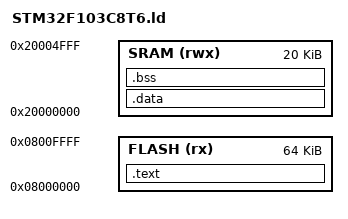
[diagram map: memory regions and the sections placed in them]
MEMORY
{
    FLASH (rx) : ORIGIN = 0x08000000, LENGTH = 64K
    SRAM (rwx) : ORIGIN = 0x20000000, LENGTH = 20K
}

ENTRY(Reset_Handler)

SECTIONS
{
    .text :
    {
        KEEP(*(.isr_vector))
        *(.text)
        *(.text*)
        *(.rodata)
        *(.rodata*)
        *(.glue_7)
        *(.glue_7t)
        *(.ARM.extab)
        *(.ARM.exidx)
        KEEP(*(.init))
        KEEP(*(.fini))
        KEEP(*(.preinit_array))
        KEEP(*(SORT_BY_INIT_PRIORITY(.init_array.*)))
        KEEP(*(.init_array))
        KEEP(*(SORT_BY_INIT_PRIORITY(.fini_array.*)))
        KEEP(*(.fini_array))
        . = ALIGN(4);
        _etext = .;
    } > FLASH

    _sidata = LOADADDR(.data);

    .data : AT (_etext)
    {
        _sdata = .;
        *(.data)
        *(.data*)
        . = ALIGN(4);
        _edata = .;
    } > SRAM

    .bss :
    {
        _sbss = .;
        *(.bss)
        *(.bss*)
        *(COMMON)
        . = ALIGN(4);
        _ebss = .;
    } > SRAM

    PROVIDE(end = _ebss);
    PROVIDE(_end = _ebss);

    _estack = ORIGIN(SRAM) + LENGTH(SRAM);
}
